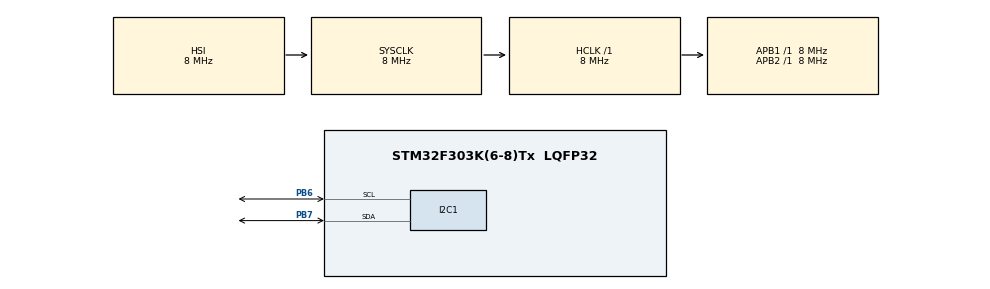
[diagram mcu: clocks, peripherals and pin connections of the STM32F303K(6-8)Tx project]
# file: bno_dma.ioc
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Dma.I2C1_RX.0.Direction=DMA_PERIPH_TO_MEMORY
Dma.I2C1_RX.0.Instance=DMA1_Channel3
Dma.I2C1_RX.0.MemDataAlignment=DMA_MDATAALIGN_BYTE
Dma.I2C1_RX.0.MemInc=DMA_MINC_ENABLE
Dma.I2C1_RX.0.Mode=DMA_NORMAL
Dma.I2C1_RX.0.PeriphDataAlignment=DMA_PDATAALIGN_BYTE
Dma.I2C1_RX.0.PeriphInc=DMA_PINC_DISABLE
Dma.I2C1_RX.0.Priority=DMA_PRIORITY_LOW
Dma.I2C1_TX.1.Direction=DMA_MEMORY_TO_PERIPH
Dma.I2C1_TX.1.Instance=DMA1_Channel2
Dma.I2C1_TX.1.MemDataAlignment=DMA_MDATAALIGN_BYTE
Dma.I2C1_TX.1.MemInc=DMA_MINC_ENABLE
Dma.I2C1_TX.1.Mode=DMA_NORMAL
Dma.I2C1_TX.1.PeriphDataAlignment=DMA_PDATAALIGN_BYTE
Dma.I2C1_TX.1.PeriphInc=DMA_PINC_DISABLE
Dma.I2C1_TX.1.Priority=DMA_PRIORITY_LOW
Dma.Request0=I2C1_RX
Dma.Request1=I2C1_TX
I2C1.Timing=0x00201D2B
Mcu.Family=STM32F3
Mcu.Name=STM32F303K(6-8)Tx
Mcu.Package=LQFP32
NVIC.DMA1_Channel2_IRQn=true\:0\:0\:false\:false\:true\:false\:true\:true
NVIC.DMA1_Channel3_IRQn=true\:0\:0\:false\:false\:true\:false\:true\:true
NVIC.I2C1_ER_IRQn=true\:0\:0\:false\:false\:true\:true\:true\:true
NVIC.I2C1_EV_IRQn=true\:0\:0\:false\:false\:true\:true\:true\:true
NVIC.PriorityGroup=NVIC_PRIORITYGROUP_4
PA13.Mode=Serial_Wire
PA13.Signal=SYS_JTMS-SWDIO
PA14.Mode=Serial_Wire
PA14.Signal=SYS_JTCK-SWCLK
PB6.Mode=I2C
PB6.Signal=I2C1_SCL
PB7.Mode=I2C
PB7.Signal=I2C1_SDA
PF0\ /\ OSC_IN.Mode=HSE-External-Oscillator
PF0\ /\ OSC_IN.Signal=RCC_OSC_IN
PF1\ /\ OSC_OUT.Mode=HSE-External-Oscillator
PF1\ /\ OSC_OUT.Signal=RCC_OSC_OUT
ProjectManager.HeapSize=0x200
ProjectManager.StackSize=0x400
ProjectManager.TargetToolchain=STM32CubeIDE
RCC.AHBFreq_Value=8000000
RCC.APB1Freq_Value=8000000
RCC.APB2Freq_Value=8000000
RCC.CortexFreq_Value=8000000
RCC.HSE_VALUE=8000000
RCC.HSI_VALUE=8000000
RCC.SYSCLKFreq_VALUE=8000000
board=custom

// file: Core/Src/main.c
/* USER CODE BEGIN Header */
/**
  ******************************************************************************
  * @file           : main.c
  * @brief          : Main program body
  ******************************************************************************
  * @attention
  *
  * Copyright (c) 2026 STMicroelectronics.
  * All rights reserved.
  *
  * This software is licensed under terms that can be found in the LICENSE file
  * in the root directory of this software component.
  * If no LICENSE file comes with this software, it is provided AS-IS.
  *
  ******************************************************************************
  */
/* USER CODE END Header */
#include "main.h"

/* USER CODE BEGIN Includes */
#include "bno055.h"
/* USER CODE END Includes */

/* USER CODE BEGIN PD */

bno055_t bno;

bno055_vec3_t accel;
bno055_vec4_t quat;
bno055_euler_t euler;
/* USER CODE END PD */

I2C_HandleTypeDef hi2c1;
DMA_HandleTypeDef hdma_i2c1_rx;
DMA_HandleTypeDef hdma_i2c1_tx;

void SystemClock_Config(void);
static void MX_GPIO_Init(void);
static void MX_DMA_Init(void);
static void MX_I2C1_Init(void);

/* USER CODE BEGIN 0 */
void HAL_I2C_MemRxCpltCallback(I2C_HandleTypeDef *hi2c) {
    if (hi2c->Instance == I2C1) {
        bno.dma_data_ready = true;
    }
}
/* USER CODE END 0 */

int main(void)
{

  /* MCU Configuration--------------------------------------------------------*/

  /* Reset of all peripherals, Initializes the Flash interface and the Systick. */
  HAL_Init();

  /* Configure the system clock */
  SystemClock_Config();

  /* Initialize all configured peripherals */
  MX_GPIO_Init();
  MX_DMA_Init();
  MX_I2C1_Init();
  /* USER CODE BEGIN 2 */
  bno.i2c = &hi2c1;
    bno.addr = BNO_ADDR_ALT;
    bno.mode = BNO_MODE_NDOF;
    HAL_Delay(500);
    if (bno055_init(&bno) != BNO_OK) {
        while (1) { }
    }

    bno055_set_unit(&bno, BNO_TEMP_UNIT_C, BNO_GYR_UNIT_DPS, BNO_ACC_UNITSEL_M_S2, BNO_EUL_UNIT_DEG);

    bno055_start_dma_read(&bno);
  /* USER CODE END 2 */

  /* Infinite loop */
  /* USER CODE BEGIN WHILE */
  while (1)
  {
	  if (bno.dma_data_ready) {

	            bno055_get_acc(&bno, &accel);
	            bno055_get_euler(&bno, &euler);
	            bno055_get_quaternion(&bno, &quat);

	            bno055_start_dma_read(&bno);
	        }
    /* USER CODE END WHILE */

  }
}

void SystemClock_Config(void)
{
  RCC_OscInitTypeDef RCC_OscInitStruct = {0};
  RCC_ClkInitTypeDef RCC_ClkInitStruct = {0};
  RCC_PeriphCLKInitTypeDef PeriphClkInit = {0};

  /** Initializes the RCC Oscillators according to the specified parameters
  * in the RCC_OscInitTypeDef structure.
  */
  RCC_OscInitStruct.OscillatorType = RCC_OSCILLATORTYPE_HSI;
  RCC_OscInitStruct.HSIState = RCC_HSI_ON;
  RCC_OscInitStruct.HSICalibrationValue = RCC_HSICALIBRATION_DEFAULT;
  RCC_OscInitStruct.PLL.PLLState = RCC_PLL_NONE;
  if (HAL_RCC_OscConfig(&RCC_OscInitStruct) != HAL_OK)
  {
    Error_Handler();
  }

  /** Initializes the CPU, AHB and APB buses clocks
  */
  RCC_ClkInitStruct.ClockType = RCC_CLOCKTYPE_HCLK|RCC_CLOCKTYPE_SYSCLK
                              |RCC_CLOCKTYPE_PCLK1|RCC_CLOCKTYPE_PCLK2;
  RCC_ClkInitStruct.SYSCLKSource = RCC_SYSCLKSOURCE_HSI;
  RCC_ClkInitStruct.AHBCLKDivider = RCC_SYSCLK_DIV1;
  RCC_ClkInitStruct.APB1CLKDivider = RCC_HCLK_DIV1;
  RCC_ClkInitStruct.APB2CLKDivider = RCC_HCLK_DIV1;

  if (HAL_RCC_ClockConfig(&RCC_ClkInitStruct, FLASH_LATENCY_0) != HAL_OK)
  {
    Error_Handler();
  }
  PeriphClkInit.PeriphClockSelection = RCC_PERIPHCLK_I2C1;
  PeriphClkInit.I2c1ClockSelection = RCC_I2C1CLKSOURCE_HSI;
  if (HAL_RCCEx_PeriphCLKConfig(&PeriphClkInit) != HAL_OK)
  {
    Error_Handler();
  }
}

static void MX_I2C1_Init(void)
{

  hi2c1.Instance = I2C1;
  hi2c1.Init.Timing = 0x00201D2B;
  hi2c1.Init.OwnAddress1 = 0;
  hi2c1.Init.AddressingMode = I2C_ADDRESSINGMODE_7BIT;
  hi2c1.Init.DualAddressMode = I2C_DUALADDRESS_DISABLE;
  hi2c1.Init.OwnAddress2 = 0;
  hi2c1.Init.OwnAddress2Masks = I2C_OA2_NOMASK;
  hi2c1.Init.GeneralCallMode = I2C_GENERALCALL_DISABLE;
  hi2c1.Init.NoStretchMode = I2C_NOSTRETCH_DISABLE;
  if (HAL_I2C_Init(&hi2c1) != HAL_OK)
  {
    Error_Handler();
  }

  /** Configure Analogue filter
  */
  if (HAL_I2CEx_ConfigAnalogFilter(&hi2c1, I2C_ANALOGFILTER_ENABLE) != HAL_OK)
  {
    Error_Handler();
  }

  /** Configure Digital filter
  */
  if (HAL_I2CEx_ConfigDigitalFilter(&hi2c1, 0) != HAL_OK)
  {
    Error_Handler();
  }

}

static void MX_DMA_Init(void)
{

  /* DMA controller clock enable */
  __HAL_RCC_DMA1_CLK_ENABLE();

  /* DMA interrupt init */
  /* DMA1_Channel2_IRQn interrupt configuration */
  HAL_NVIC_SetPriority(DMA1_Channel2_IRQn, 0, 0);
  HAL_NVIC_EnableIRQ(DMA1_Channel2_IRQn);
  /* DMA1_Channel3_IRQn interrupt configuration */
  HAL_NVIC_SetPriority(DMA1_Channel3_IRQn, 0, 0);
  HAL_NVIC_EnableIRQ(DMA1_Channel3_IRQn);

}

static void MX_GPIO_Init(void)
{

  /* GPIO Ports Clock Enable */
  __HAL_RCC_GPIOF_CLK_ENABLE();
  __HAL_RCC_GPIOA_CLK_ENABLE();
  __HAL_RCC_GPIOB_CLK_ENABLE();

}

void Error_Handler(void)
{
  __disable_irq();
  while (1)
  {
  }
}
